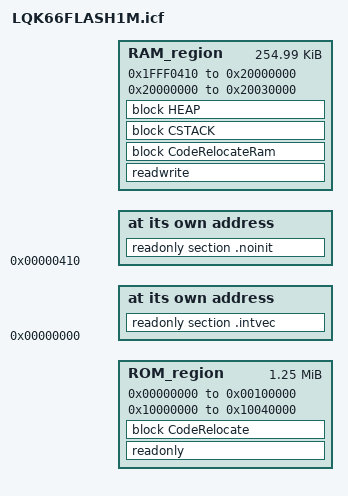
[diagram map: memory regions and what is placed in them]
/*###ICF### Section handled by ICF editor, don't touch! ****/
/*-Editor annotation file-*/
/*-北京龙邱智能科技有限公司2016-08-23配置-*/
/* IcfEditorFile="$TOOLKIT_DIR$\config\ide\IcfEditor\cortex_v1_0.xml" */
/*-Specials-*/
define symbol __ICFEDIT_intvec_start__ = 0x00000000;
/*-Memory Regions-*/
define symbol __ICFEDIT_region_ROM_start__ = 0x00000000;
define symbol __ICFEDIT_region_ROM_end__   = 0x00100000;
define symbol __ICFEDIT_region_RAM_start__ = 0x1FFF0410;
define symbol __ICFEDIT_region_RAM_end__   = 0x20000000;
/*-Sizes-*/
define symbol __ICFEDIT_size_cstack__ = 0x2000;
define symbol __ICFEDIT_size_heap__   = 0x4000;
/**** End of ICF editor section. ###ICF###*/

define symbol __region_FlexNVM_start__  = 0x10000000;
define symbol __region_FlexNVM_end__    = 0x10040000;

define symbol __region_RAM2_start__ = 0x20000000;
define symbol __region_RAM2_end__   = 0x20030000;

define exported symbol __VECTOR_TABLE = 0x00000000;
define exported symbol __VECTOR_RAM = 0x1fff0000;

define exported symbol __BOOT_STACK_ADDRESS = __region_RAM2_end__ - 8;	//0x2002FFF8;

define symbol __code_start__ = 0x00000410;

define memory mem with size = 4G;
define region ROM_region   = mem:[from __ICFEDIT_region_ROM_start__   to __ICFEDIT_region_ROM_end__] | mem:[from __region_FlexNVM_start__ to __region_FlexNVM_end__];
define region RAM_region   = mem:[from __ICFEDIT_region_RAM_start__   to __ICFEDIT_region_RAM_end__] | mem:[from __region_RAM2_start__ to __region_RAM2_end__];

define block CSTACK    with alignment = 8, size = __ICFEDIT_size_cstack__   { };
define block HEAP      with alignment = 8, size = __ICFEDIT_size_heap__     { };

initialize manually { readwrite };
initialize manually { section .data};
initialize manually { section .textrw };
do not initialize  { section .noinit };

define block CodeRelocate { section .textrw_init };
define block CodeRelocateRam { section .textrw };

place at address mem:__ICFEDIT_intvec_start__ { readonly section .intvec };
place at address mem:__code_start__ { readonly section .noinit };

place in ROM_region   { readonly, block CodeRelocate};

place in RAM_region   { readwrite, block CodeRelocateRam,
                        block CSTACK, block HEAP };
